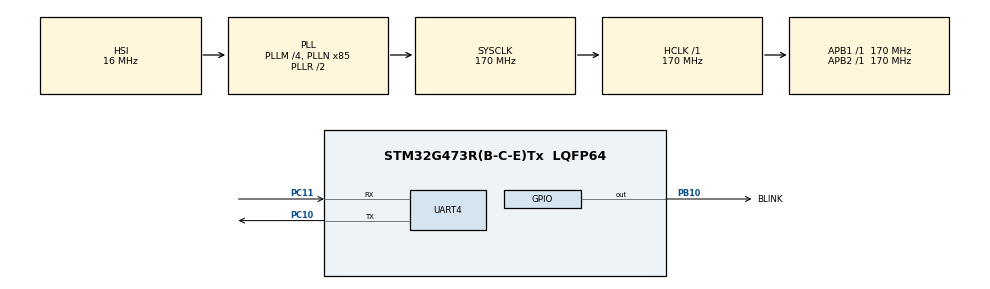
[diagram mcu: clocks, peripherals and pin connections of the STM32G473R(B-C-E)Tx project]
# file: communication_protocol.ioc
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Dma.Request0=UART4_RX
Dma.UART4_RX.0.Direction=DMA_PERIPH_TO_MEMORY
Dma.UART4_RX.0.EventEnable=DISABLE
Dma.UART4_RX.0.Instance=DMA1_Channel1
Dma.UART4_RX.0.MemDataAlignment=DMA_MDATAALIGN_BYTE
Dma.UART4_RX.0.MemInc=DMA_MINC_ENABLE
Dma.UART4_RX.0.Mode=DMA_NORMAL
Dma.UART4_RX.0.PeriphDataAlignment=DMA_PDATAALIGN_BYTE
Dma.UART4_RX.0.PeriphInc=DMA_PINC_DISABLE
Dma.UART4_RX.0.Polarity=HAL_DMAMUX_REQ_GEN_RISING
Dma.UART4_RX.0.Priority=DMA_PRIORITY_LOW
Dma.UART4_RX.0.RequestNumber=1
Dma.UART4_RX.0.SignalID=NONE
Dma.UART4_RX.0.SyncEnable=DISABLE
Dma.UART4_RX.0.SyncPolarity=HAL_DMAMUX_SYNC_NO_EVENT
Dma.UART4_RX.0.SyncRequestNumber=1
Dma.UART4_RX.0.SyncSignalID=NONE
Mcu.Family=STM32G4
Mcu.Name=STM32G473R(B-C-E)Tx
Mcu.Package=LQFP64
NVIC.DMA1_Channel1_IRQn=true\:0\:0\:false\:false\:true\:false\:true\:true
NVIC.PriorityGroup=NVIC_PRIORITYGROUP_4
PA13.Mode=Serial_Wire
PA13.Signal=SYS_JTMS-SWDIO
PA14.Mode=Serial_Wire
PA14.Signal=SYS_JTCK-SWCLK
PB10.GPIO_Label=BLINK
PB10.Signal=GPIO_Output
PC10.Mode=Asynchronous
PC10.Signal=UART4_TX
PC11.Mode=Asynchronous
PC11.Signal=UART4_RX
PF0-OSC_IN.Mode=HSE-External-Oscillator
PF0-OSC_IN.Signal=RCC_OSC_IN
PF1-OSC_OUT.Mode=HSE-External-Oscillator
PF1-OSC_OUT.Signal=RCC_OSC_OUT
ProjectManager.HeapSize=0x200
ProjectManager.StackSize=0x400
ProjectManager.TargetToolchain=STM32CubeIDE
RCC.ADC12Freq_Value=170000000
RCC.ADC345Freq_Value=170000000
RCC.AHBFreq_Value=170000000
RCC.APB1Freq_Value=170000000
RCC.APB1TimFreq_Value=170000000
RCC.APB2Freq_Value=170000000
RCC.APB2TimFreq_Value=170000000
RCC.CortexFreq_Value=170000000
RCC.EXTERNAL_CLOCK_VALUE=12288000
RCC.HCLKFreq_Value=170000000
RCC.HSE_VALUE=16000000
RCC.HSI48_VALUE=48000000
RCC.HSI_VALUE=16000000
RCC.LSE_VALUE=32768
RCC.PLLM=RCC_PLLM_DIV4
RCC.PLLN=85
RCC.SYSCLKFreq_VALUE=170000000
RCC.SYSCLKSource=RCC_SYSCLKSOURCE_PLLCLK
RCC.USBFreq_Value=170000000
RCC.VCOOutputFreq_Value=340000000
VP_SYS_VS_DBSignals.Mode=DisableDeadBatterySignals
board=custom

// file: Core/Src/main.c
/* USER CODE BEGIN Header */
/**
  ******************************************************************************
  * @file           : main.c
  * @brief          : Main program body
  ******************************************************************************
  * @attention
  *
  * Copyright (c) 2025 STMicroelectronics.
  * All rights reserved.
  *
  * This software is licensed under terms that can be found in the LICENSE file
  * in the root directory of this software component.
  * If no LICENSE file comes with this software, it is provided AS-IS.
  *
  ******************************************************************************
  */
/* USER CODE END Header */
#include "main.h"

/* USER CODE BEGIN Includes */
#include <stdio.h>         //for printf
#include <stdbool.h>       //for bool
#include <string.h>        //for memse

/* USER CODE END Includes */

/* USER CODE BEGIN PD */
#define MAX_DATA_LEN 12            // Maksimum veri boyutu (başlık + veri boyu + tür + adres + veri)
uint8_t uartHeader[1];             // Başlık (2) + Veri boyu (1) + Tür(1) + Adres + Veri
uint8_t uartData[MAX_DATA_LEN];    // Başlık (2) + Veri boyu (1) + Tür(1) + Adres + Veri
uint8_t dataLen = 0;               // Alınan veri boyutu
//volatile bool dataCheck = false;   // veri kontrolü için değişken
volatile bool headerCheck = false; // Başlık kontrolü için değişken
volatile bool header0 = false;     // başlık 1. bayte kontrolü için değişken
volatile bool header1 = false;     // başlık 2. bayte kontrolü için değişken
volatile bool header2 = false;     // başlık 3. bayte kontrolü için değişken
// Timeout için
volatile uint32_t dmaStartTick = 0;  // DMA başladığında zamanı kaydedeceksin
volatile uint8_t waitingForData = 0; // Şu anda veri bekliyor musun?
/* USER CODE END PD */

UART_HandleTypeDef huart4;
DMA_HandleTypeDef hdma_uart4_rx;

void SystemClock_Config(void);
static void MX_GPIO_Init(void);
static void MX_DMA_Init(void);
static void MX_UART4_Init(void);
/* USER CODE BEGIN PFP */
void ProcessIncomingData(uint8_t *data, uint8_t len);//main.h dosyasına da yazılabilir.
/* USER CODE END PFP */

/* USER CODE BEGIN 0 */
void HAL_UART_RxCpltCallback(UART_HandleTypeDef *huart) // Mesajın DMA ile alınması
{
	/*
	 * DMA komutu yazılırken veri boyutu belirtilir.
	 * Eğer gelen mesajın veri boyutu, belirtilen değerden küçük olursa(eksik mesaj gelirse) bu fonksiyon çalışmaz ve muhtemelen donma gerçekleşir.
	 * Eğer gelen mesajın veri boyutu, belirtilen değerden büyük olursa(fazla mesaj gelirse) bu veri kaybına sebep olur.
	 * Yani burada belirtilecek olan dataLen, mesajdan az ya da çok olmamalı ---> HAL_UART_Receive_DMA(&huart4, (uint8_t *)uartData, dataLen);
	 * dataLen başlık kısmının boyutunu içermez, kendinden sonra gelecek olan verinin boyutunu belirtir.
	 */
  if (huart->Instance == UART4) // Eğer UART4 kullanılıyorsa
  {
    if (!header0)
    {
      if (uartHeader[0] == 0x45)                               // Başlık kontrolü
        header0 = true;                                        // Başlık kontrolü başarılı
      HAL_UART_Receive_DMA(&huart4, (uint8_t *)uartHeader, 1); // Başlık kısmını dinlemeye devam et
    }
    else if (header0 && !header1)
    {
      if (uartHeader[0] == 0x43) // Başlık kontrolü
        header1 = true;
      else
        header0 = false;                                       // Başlık kontrolü başarısız, başlık kısmını sıfırla
      HAL_UART_Receive_DMA(&huart4, (uint8_t *)uartHeader, 1); // Başlık kısmını dinlemeye devam et
    }
    else if (header0 && header1 && !header2)
    {
      if (uartHeader[0] == 0x45) // Başlık kontrolü
        header2 = true;
      else
      {
    	  header0 = false;
    	  header1 = false;
      }// Başlık kontrolü başarısız, başlık kısmını sıfırla
      HAL_UART_Receive_DMA(&huart4, (uint8_t *)uartHeader, 1); // Başlık kısmını dinlemeye devam et
    }
    else if (header0 && header1 && header2 && !headerCheck) // Başlık kontrolü
    {

      // DATALEN değeri önemli. Eğer gelen veri ondan az ya da çok olursa haberleşme hatası olur ve haberleşme devam etmesi için kartı resetlemek gerekir.

      dataLen = uartHeader[0];    // Veri boyutunu al
      if (dataLen > MAX_DATA_LEN) // Eğer veri boyutu MAX_DATA_LEN'den büyükse
      {
        header0 = false;                                         // Başlık kısmını sıfırla
        header1 = false;                                         // Başlık kısmını sıfırla
        header2 = false;                                         // Başlık kısmını sıfırla
        HAL_UART_Receive_DMA(&huart4, (uint8_t *)uartHeader, 1); // Başlık kısmını dinlemeye devam et
      }
      else
      {
        headerCheck = true;                                          // Başlık kontrolü başarılı
        dmaStartTick = HAL_GetTick();                                // *** Timeout timer'ı başlat ***
        waitingForData = 1;                                          // *** Timeout bekleme modunu aktif et ***
        HAL_UART_Receive_DMA(&huart4, (uint8_t *)uartData, dataLen); // Gelen veriyi al
      }
    }
    else if (headerCheck)
    {
      headerCheck = false; // Başlık kontrolünü sıfırla
      header0 = false;     // Başlık kısmını sıfırla
      header1 = false;     // Başlık kısmını sıfırla
      header2 = false;     // Başlık kısmını sıfırla

      waitingForData = 0; // *** Timeout bekleme modunu kapat ***

      ProcessIncomingData(&uartData[0], dataLen);   // Gelen veriyi işleme fonksiyonunu çağırıyoruz
      HAL_UART_Receive_DMA(&huart4, uartHeader, 1); // Başlık kısmını dinlemeye devam et
    }
  }
}

void ProcessIncomingData(uint8_t *data, uint8_t len) // VERİLERİN İŞLENME FONKSİYONU
{
	  switch (data[0]) // Gelen verinin türüne göre işlem yapılıyor
	  {
	  case 0x53 : //String işlemi
	  {
	   switch (data[1])
				   {
	   case 0x00: // Mesaj yok, default mesajı yazdır.
	   {
		   printf("Mesaj Yok\n");
	   }
	   break;

	   case 0x01: // Haberleşme ile gelen mesajı yazdır.
	   {
		   for (int i = 2; i< len; i++)
			   {
			   printf("%c", data[i]); //ASCII karşılığını karakter olarak yazdırır.
			   /*
			    *printf("%u", data[i]); //Byte değerini yazdırır
			    * printf("%02X ", data[i]); // HEX değerini yazdırır
			    */
			   }
		   printf("\n");
	   }break;

	   default: break;
	   }

	  }break;

	  case 0x0D : //Dijital işlemler
	  {
		  switch(data[1])
		  {
		  case 0x0B : //BLINK LED
		  {
			  if (data[2])
				  HAL_GPIO_WritePin(GPIOB, BLINK_Pin , GPIO_PIN_SET);
			  else
				  HAL_GPIO_WritePin(GPIOB, BLINK_Pin , GPIO_PIN_RESET);
		  }break;

		  default: break;
		  }
	  }break;

	   default: break;
	  }

}

int __io_putchar(int ch) // printf işlevini UART4e yönlendiren fonksiyon
{
  HAL_UART_Transmit(&huart4, (uint8_t *)&ch, 1, HAL_MAX_DELAY);
  return ch;
}
/* USER CODE END 0 */

int main(void)
{

  /* MCU Configuration--------------------------------------------------------*/

  /* Reset of all peripherals, Initializes the Flash interface and the Systick. */
  HAL_Init();

  /* Configure the system clock */
  SystemClock_Config();

  /* Initialize all configured peripherals */
  MX_GPIO_Init();
  MX_DMA_Init();
  MX_UART4_Init();
  /* USER CODE BEGIN 2 */

  HAL_UART_Init(&huart4);
  HAL_UART_Receive_DMA(&huart4, (uint8_t *)uartHeader, 1); // DMA başlatılıyor, uartHeader 1 byte alınacak
  /* USER CODE END 2 */

  /* Infinite loop */
  /* USER CODE BEGIN WHILE */
  while (1)
  {
	  if (waitingForData)
      {
        if (HAL_GetTick() - dmaStartTick > 100) // 100 ms örnek, ihtiyaca göre ayarlayabilirsin
        {
          // Timeout oldu, sistem başa dönsün
          header0 = false;
          header1 = false;
          headerCheck = false;
          waitingForData = 0;
          HAL_UART_Receive_DMA(&huart4, uartHeader, 1); // Baştan başla
        }
      }

    /* USER CODE END WHILE */

  }
}

void SystemClock_Config(void)
{
  RCC_OscInitTypeDef RCC_OscInitStruct = {0};
  RCC_ClkInitTypeDef RCC_ClkInitStruct = {0};

  /** Configure the main internal regulator output voltage
  */
  HAL_PWREx_ControlVoltageScaling(PWR_REGULATOR_VOLTAGE_SCALE1_BOOST);

  /** Initializes the RCC Oscillators according to the specified parameters
  * in the RCC_OscInitTypeDef structure.
  */
  RCC_OscInitStruct.OscillatorType = RCC_OSCILLATORTYPE_HSI;
  RCC_OscInitStruct.HSIState = RCC_HSI_ON;
  RCC_OscInitStruct.HSICalibrationValue = RCC_HSICALIBRATION_DEFAULT;
  RCC_OscInitStruct.PLL.PLLState = RCC_PLL_ON;
  RCC_OscInitStruct.PLL.PLLSource = RCC_PLLSOURCE_HSI;
  RCC_OscInitStruct.PLL.PLLM = RCC_PLLM_DIV4;
  RCC_OscInitStruct.PLL.PLLN = 85;
  RCC_OscInitStruct.PLL.PLLP = RCC_PLLP_DIV2;
  RCC_OscInitStruct.PLL.PLLQ = RCC_PLLQ_DIV2;
  RCC_OscInitStruct.PLL.PLLR = RCC_PLLR_DIV2;
  if (HAL_RCC_OscConfig(&RCC_OscInitStruct) != HAL_OK)
  {
    Error_Handler();
  }

  /** Initializes the CPU, AHB and APB buses clocks
  */
  RCC_ClkInitStruct.ClockType = RCC_CLOCKTYPE_HCLK|RCC_CLOCKTYPE_SYSCLK
                              |RCC_CLOCKTYPE_PCLK1|RCC_CLOCKTYPE_PCLK2;
  RCC_ClkInitStruct.SYSCLKSource = RCC_SYSCLKSOURCE_PLLCLK;
  RCC_ClkInitStruct.AHBCLKDivider = RCC_SYSCLK_DIV1;
  RCC_ClkInitStruct.APB1CLKDivider = RCC_HCLK_DIV1;
  RCC_ClkInitStruct.APB2CLKDivider = RCC_HCLK_DIV1;

  if (HAL_RCC_ClockConfig(&RCC_ClkInitStruct, FLASH_LATENCY_4) != HAL_OK)
  {
    Error_Handler();
  }
}

static void MX_UART4_Init(void)
{

  huart4.Instance = UART4;
  huart4.Init.BaudRate = 115200;
  huart4.Init.WordLength = UART_WORDLENGTH_8B;
  huart4.Init.StopBits = UART_STOPBITS_1;
  huart4.Init.Parity = UART_PARITY_NONE;
  huart4.Init.Mode = UART_MODE_TX_RX;
  huart4.Init.HwFlowCtl = UART_HWCONTROL_NONE;
  huart4.Init.OverSampling = UART_OVERSAMPLING_16;
  huart4.Init.OneBitSampling = UART_ONE_BIT_SAMPLE_DISABLE;
  huart4.Init.ClockPrescaler = UART_PRESCALER_DIV1;
  huart4.AdvancedInit.AdvFeatureInit = UART_ADVFEATURE_NO_INIT;
  if (HAL_UART_Init(&huart4) != HAL_OK)
  {
    Error_Handler();
  }
  if (HAL_UARTEx_SetTxFifoThreshold(&huart4, UART_TXFIFO_THRESHOLD_1_8) != HAL_OK)
  {
    Error_Handler();
  }
  if (HAL_UARTEx_SetRxFifoThreshold(&huart4, UART_RXFIFO_THRESHOLD_1_8) != HAL_OK)
  {
    Error_Handler();
  }
  if (HAL_UARTEx_DisableFifoMode(&huart4) != HAL_OK)
  {
    Error_Handler();
  }

}

static void MX_DMA_Init(void)
{

  /* DMA controller clock enable */
  __HAL_RCC_DMAMUX1_CLK_ENABLE();
  __HAL_RCC_DMA1_CLK_ENABLE();

  /* DMA interrupt init */
  /* DMA1_Channel1_IRQn interrupt configuration */
  HAL_NVIC_SetPriority(DMA1_Channel1_IRQn, 0, 0);
  HAL_NVIC_EnableIRQ(DMA1_Channel1_IRQn);

}

static void MX_GPIO_Init(void)
{
  GPIO_InitTypeDef GPIO_InitStruct = {0};

  /* GPIO Ports Clock Enable */
  __HAL_RCC_GPIOF_CLK_ENABLE();
  __HAL_RCC_GPIOB_CLK_ENABLE();
  __HAL_RCC_GPIOA_CLK_ENABLE();
  __HAL_RCC_GPIOC_CLK_ENABLE();

  /*Configure GPIO pin Output Level */
  HAL_GPIO_WritePin(BLINK_GPIO_Port, BLINK_Pin, GPIO_PIN_RESET);

  /*Configure GPIO pin : BLINK_Pin */
  GPIO_InitStruct.Pin = BLINK_Pin;
  GPIO_InitStruct.Mode = GPIO_MODE_OUTPUT_PP;
  GPIO_InitStruct.Pull = GPIO_NOPULL;
  GPIO_InitStruct.Speed = GPIO_SPEED_FREQ_LOW;
  HAL_GPIO_Init(BLINK_GPIO_Port, &GPIO_InitStruct);

}

void Error_Handler(void)
{
  __disable_irq();
  while (1)
  {
  }
}
